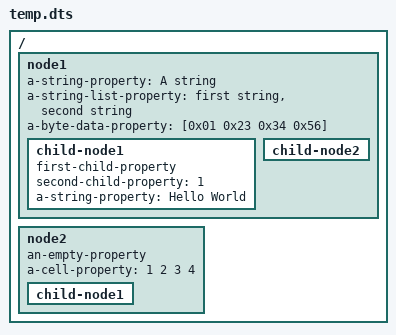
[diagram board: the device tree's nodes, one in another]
#include "xxx.dtsi"

/ {
	node1 {
		a-string-property = "A string";
		a-string-list-property = "first string", "second string";
		a-byte-data-property = [0x01 0x23 0x34 0x56];
		child-node1 {
			first-child-property;
			second-child-property = <1>;
			a-string-property = "Hello World";
		};
		child-node2 {
		
		};
	};
	node2 {
		an-empty-property;
		a-cell-property = <1 2 3 4>;
		child-node1 {
		
		};
	};
};
